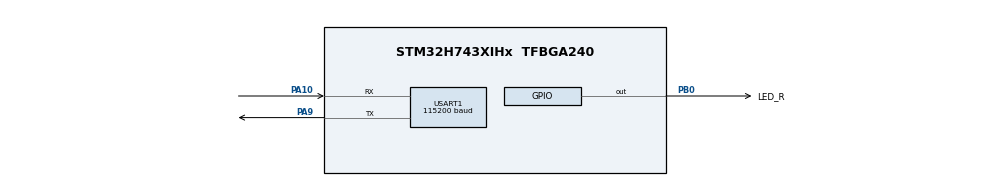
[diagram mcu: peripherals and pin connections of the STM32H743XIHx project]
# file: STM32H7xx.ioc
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CORTEX_M7.AccessPermission_S-Cortex_Memory_Protection_Unit_Region1_Settings_S=MPU_REGION_FULL_ACCESS
CORTEX_M7.AccessPermission_S-Cortex_Memory_Protection_Unit_Region2_Settings_S=MPU_REGION_FULL_ACCESS
CORTEX_M7.AccessPermission_S-Cortex_Memory_Protection_Unit_Region3_Settings_S=MPU_REGION_FULL_ACCESS
CORTEX_M7.AccessPermission_Spec=MPU_REGION_FULL_ACCESS
CORTEX_M7.BaseAddress_S-Cortex_Memory_Protection_Unit_Region1_Settings_S=0x24000000
CORTEX_M7.BaseAddress_S-Cortex_Memory_Protection_Unit_Region2_Settings_S=0x30000000
CORTEX_M7.BaseAddress_S-Cortex_Memory_Protection_Unit_Region3_Settings_S=0x38000000
CORTEX_M7.BaseAddress_Spec=0x20000000
CORTEX_M7.CPU_DCache=Enabled
CORTEX_M7.CPU_ICache=Enabled
CORTEX_M7.DisableExec_Spec=MPU_INSTRUCTION_ACCESS_ENABLE
CORTEX_M7.Enable_S-Cortex_Memory_Protection_Unit_Region1_Settings_S=MPU_REGION_ENABLE
CORTEX_M7.Enable_S-Cortex_Memory_Protection_Unit_Region2_Settings_S=MPU_REGION_ENABLE
CORTEX_M7.Enable_S-Cortex_Memory_Protection_Unit_Region3_Settings_S=MPU_REGION_ENABLE
CORTEX_M7.Enable_S-Cortex_Memory_Protection_Unit_Region4_Settings_S=__NULL
CORTEX_M7.Enable_S-Cortex_Memory_Protection_Unit_Region5_Settings_S=__NULL
CORTEX_M7.IsBufferable_S-Cortex_Memory_Protection_Unit_Region1_Settings_S=MPU_ACCESS_BUFFERABLE
CORTEX_M7.IsBufferable_S-Cortex_Memory_Protection_Unit_Region2_Settings_S=MPU_ACCESS_BUFFERABLE
CORTEX_M7.IsBufferable_S-Cortex_Memory_Protection_Unit_Region3_Settings_S=MPU_ACCESS_BUFFERABLE
CORTEX_M7.IsBufferable_Spec=MPU_ACCESS_BUFFERABLE
CORTEX_M7.IsCacheable_S-Cortex_Memory_Protection_Unit_Region1_Settings_S=MPU_ACCESS_CACHEABLE
CORTEX_M7.IsCacheable_S-Cortex_Memory_Protection_Unit_Region2_Settings_S=MPU_ACCESS_CACHEABLE
CORTEX_M7.IsCacheable_S-Cortex_Memory_Protection_Unit_Region3_Settings_S=MPU_ACCESS_CACHEABLE
CORTEX_M7.IsCacheable_Spec=MPU_ACCESS_CACHEABLE
CORTEX_M7.IsShareable_Spec=MPU_ACCESS_NOT_SHAREABLE
CORTEX_M7.Size_S-Cortex_Memory_Protection_Unit_Region1_Settings_S=MPU_REGION_SIZE_512KB
CORTEX_M7.Size_S-Cortex_Memory_Protection_Unit_Region2_Settings_S=MPU_REGION_SIZE_512KB
CORTEX_M7.Size_S-Cortex_Memory_Protection_Unit_Region3_Settings_S=MPU_REGION_SIZE_64KB
CORTEX_M7.Size_Spec=MPU_REGION_SIZE_128KB
CORTEX_M7.SubRegionDisable_Spec=0x00
CORTEX_M7.default_mode_Activation=1
Mcu.Family=STM32H7
Mcu.Name=STM32H743XIHx
Mcu.Package=TFBGA240
NVIC.PriorityGroup=NVIC_PRIORITYGROUP_2
NVIC.USART1_IRQn=true\:2\:2\:true\:false\:true\:true\:true\:true
PA10.GPIO_Speed=GPIO_SPEED_FREQ_VERY_HIGH
PA10.Mode=Asynchronous
PA10.Signal=USART1_RX
PA13\ (JTMS/SWDIO).Mode=Serial_Wire
PA13\ (JTMS/SWDIO).Signal=DEBUG_JTMS-SWDIO
PA14\ (JTCK/SWCLK).Mode=Serial_Wire
PA14\ (JTCK/SWCLK).Signal=DEBUG_JTCK-SWCLK
PA9.GPIO_Speed=GPIO_SPEED_FREQ_VERY_HIGH
PA9.Mode=Asynchronous
PA9.Signal=USART1_TX
PB0.GPIO_Label=LED_R
PB0.GPIO_PuPd=GPIO_PULLUP
PB0.GPIO_Speed=GPIO_SPEED_FREQ_HIGH
PB0.PinState=GPIO_PIN_SET
PB0.Signal=GPIO_Output
PC14-OSC32_IN\ (OSC32_IN).Mode=LSE-External-Oscillator
PC14-OSC32_IN\ (OSC32_IN).Signal=RCC_OSC32_IN
PC15-OSC32_OUT\ (OSC32_OUT).Mode=LSE-External-Oscillator
PC15-OSC32_OUT\ (OSC32_OUT).Signal=RCC_OSC32_OUT
PH0-OSC_IN\ (PH0).Mode=HSE-External-Oscillator
PH0-OSC_IN\ (PH0).Signal=RCC_OSC_IN
PH1-OSC_OUT\ (PH1).Mode=HSE-External-Oscillator
PH1-OSC_OUT\ (PH1).Signal=RCC_OSC_OUT
ProjectManager.HeapSize=0x200
ProjectManager.StackSize=0x400
ProjectManager.TargetToolchain=MDK-ARM V5.32
RCC.ADCFreq_Value=75000000
RCC.APB1Freq_Value=120000000
RCC.APB2Freq_Value=120000000
RCC.APB3Freq_Value=120000000
RCC.APB4Freq_Value=120000000
RCC.CortexFreq_Value=480000000
RCC.D1PPRE=RCC_APB3_DIV2
RCC.D2PPRE1=RCC_APB1_DIV2
RCC.D2PPRE2=RCC_APB2_DIV2
RCC.D3PPRE=RCC_APB4_DIV2
RCC.DIVM1=5
RCC.DIVM2=2
RCC.DIVN1=192
RCC.DIVN2=12
RCC.HCLKFreq_Value=240000000
RCC.HPRE=RCC_HCLK_DIV2
RCC.PLL2FRACN=0
RCC.PLL3FRACN=0
RCC.PLLFRACN=0
RCC.PLLSourceVirtual=RCC_PLLSOURCE_HSE
RCC.PWR_Regulator_Voltage_Scale=PWR_REGULATOR_VOLTAGE_SCALE0
RCC.ProductRev=revV
RCC.RCC_TIM_PRescaler_Selection=RCC_TIMPRES_ACTIVATED
RCC.SYSCLKFreq_VALUE=480000000
RCC.SYSCLKSource=RCC_SYSCLKSOURCE_PLLCLK
RCC.USBFreq_Value=480000000
RCC.VDD_VALUE=3.3
USART1.BaudRate=115200
USART1.VirtualMode-Asynchronous=VM_ASYNC
board=custom

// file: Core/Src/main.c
/* USER CODE BEGIN Header */
/**
  ******************************************************************************
  * @file           : main.c
  * @brief          : Main program body
  ******************************************************************************
  * @attention
  *
  * Copyright (c) 2023 STMicroelectronics.
  * All rights reserved.
  *
  * This software is licensed under terms that can be found in the LICENSE file
  * in the root directory of this software component.
  * If no LICENSE file comes with this software, it is provided AS-IS.
  *
  ******************************************************************************
  */
/* USER CODE END Header */
#include "main.h"
#include "usart.h"
#include "gpio.h"

/* USER CODE BEGIN Includes */

#include "stdio.h"
#include "string.h"
#include "stdlib.h"

/* USER CODE END Includes */

void SystemClock_Config(void);
void PeriphCommonClock_Config(void);
static void MPU_Config(void);

/* USER CODE BEGIN 0 */

/*
*********************************************************************************************************
*	函 数 名: PrintfLogo
*	功能说明: 打印例程名称和例程发布日期, 接上串口线后，打开PC机的超级终端软件可以观察结果
*	形    参: 无
*	返 回 值: 无
*********************************************************************************************************
*/
static void Printf_Logo(void)
{
	printf("*************************************************************\r\n");

    uint32_t CPU_Sn0, CPU_Sn1, CPU_Sn2;

    CPU_Sn0 = *(__IO uint32_t*)(0x1FF1E800);
    CPU_Sn1 = *(__IO uint32_t*)(0x1FF1E800 + 4);
    CPU_Sn2 = *(__IO uint32_t*)(0x1FF1E800 + 8);

    printf("CPU : STM32H743XIH6, BGA240, 主频: %dMHz\r\n", SystemCoreClock / 1000000);
    printf("UID = %08X %08X %08X", CPU_Sn2, CPU_Sn1, CPU_Sn0);

	printf("*************************************************************\r\n");
	printf("* 例程名称 : 串口通信\r\n");	/* 打印例程名称 */
    printf("* 例程现象 : 串口自动发送接收到的数据\r\n");	/* 打印例程名称 */

	printf("*************************************************************\r\n");
}

/* USER CODE END 0 */

int main(void)
{

  /* MPU Configuration--------------------------------------------------------*/
  MPU_Config();

  /* Enable the CPU Cache */

  /* Enable I-Cache---------------------------------------------------------*/
  SCB_EnableICache();

  /* Enable D-Cache---------------------------------------------------------*/
  SCB_EnableDCache();

  /* MCU Configuration--------------------------------------------------------*/

  /* Reset of all peripherals, Initializes the Flash interface and the Systick. */
  HAL_Init();

  /* Configure the system clock */
  SystemClock_Config();

/* Configure the peripherals common clocks */
  PeriphCommonClock_Config();

  /* Initialize all configured peripherals */
  MX_GPIO_Init();
  MX_USART1_UART_Init();
  /* USER CODE BEGIN 2 */

    Printf_Logo();

  /* USER CODE END 2 */

  /* Infinite loop */
  /* USER CODE BEGIN WHILE */
  while (1)
  {
      LED_R_TOGGLE();
      HAL_Delay(100);

    /* USER CODE END WHILE */

  }
}

void SystemClock_Config(void)
{
  RCC_OscInitTypeDef RCC_OscInitStruct = {0};
  RCC_ClkInitTypeDef RCC_ClkInitStruct = {0};

  /** Supply configuration update enable
  */
  HAL_PWREx_ConfigSupply(PWR_LDO_SUPPLY);

  /** Configure the main internal regulator output voltage
  */
  __HAL_PWR_VOLTAGESCALING_CONFIG(PWR_REGULATOR_VOLTAGE_SCALE1);

  while(!__HAL_PWR_GET_FLAG(PWR_FLAG_VOSRDY)) {}

  __HAL_RCC_SYSCFG_CLK_ENABLE();
  __HAL_PWR_VOLTAGESCALING_CONFIG(PWR_REGULATOR_VOLTAGE_SCALE0);

  while(!__HAL_PWR_GET_FLAG(PWR_FLAG_VOSRDY)) {}

  /** Initializes the RCC Oscillators according to the specified parameters
  * in the RCC_OscInitTypeDef structure.
  */
  RCC_OscInitStruct.OscillatorType = RCC_OSCILLATORTYPE_HSE;
  RCC_OscInitStruct.HSEState = RCC_HSE_ON;
  RCC_OscInitStruct.PLL.PLLState = RCC_PLL_ON;
  RCC_OscInitStruct.PLL.PLLSource = RCC_PLLSOURCE_HSE;
  RCC_OscInitStruct.PLL.PLLM = 5;
  RCC_OscInitStruct.PLL.PLLN = 192;
  RCC_OscInitStruct.PLL.PLLP = 2;
  RCC_OscInitStruct.PLL.PLLQ = 2;
  RCC_OscInitStruct.PLL.PLLR = 2;
  RCC_OscInitStruct.PLL.PLLRGE = RCC_PLL1VCIRANGE_2;
  RCC_OscInitStruct.PLL.PLLVCOSEL = RCC_PLL1VCOWIDE;
  RCC_OscInitStruct.PLL.PLLFRACN = 0;
  if (HAL_RCC_OscConfig(&RCC_OscInitStruct) != HAL_OK)
  {
    Error_Handler();
  }

  /** Initializes the CPU, AHB and APB buses clocks
  */
  RCC_ClkInitStruct.ClockType = RCC_CLOCKTYPE_HCLK|RCC_CLOCKTYPE_SYSCLK
                              |RCC_CLOCKTYPE_PCLK1|RCC_CLOCKTYPE_PCLK2
                              |RCC_CLOCKTYPE_D3PCLK1|RCC_CLOCKTYPE_D1PCLK1;
  RCC_ClkInitStruct.SYSCLKSource = RCC_SYSCLKSOURCE_PLLCLK;
  RCC_ClkInitStruct.SYSCLKDivider = RCC_SYSCLK_DIV1;
  RCC_ClkInitStruct.AHBCLKDivider = RCC_HCLK_DIV2;
  RCC_ClkInitStruct.APB3CLKDivider = RCC_APB3_DIV2;
  RCC_ClkInitStruct.APB1CLKDivider = RCC_APB1_DIV2;
  RCC_ClkInitStruct.APB2CLKDivider = RCC_APB2_DIV2;
  RCC_ClkInitStruct.APB4CLKDivider = RCC_APB4_DIV2;

  if (HAL_RCC_ClockConfig(&RCC_ClkInitStruct, FLASH_LATENCY_4) != HAL_OK)
  {
    Error_Handler();
  }
}

void PeriphCommonClock_Config(void)
{
  RCC_PeriphCLKInitTypeDef PeriphClkInitStruct = {0};

  /** Initializes the peripherals clock
  */
  PeriphClkInitStruct.PeriphClockSelection = RCC_PERIPHCLK_TIM;
  PeriphClkInitStruct.TIMPresSelection = RCC_TIMPRES_ACTIVATED;

  if (HAL_RCCEx_PeriphCLKConfig(&PeriphClkInitStruct) != HAL_OK)
  {
    Error_Handler();
  }
}

 /* MPU Configuration */

void MPU_Config(void)
{
  MPU_Region_InitTypeDef MPU_InitStruct = {0};

  /* Disables the MPU */
  HAL_MPU_Disable();

  /** Initializes and configures the Region and the memory to be protected
  */
  MPU_InitStruct.Enable = MPU_REGION_ENABLE;
  MPU_InitStruct.Number = MPU_REGION_NUMBER0;
  MPU_InitStruct.BaseAddress = 0x20000000;
  MPU_InitStruct.Size = MPU_REGION_SIZE_128KB;
  MPU_InitStruct.SubRegionDisable = 0x00;
  MPU_InitStruct.TypeExtField = MPU_TEX_LEVEL0;
  MPU_InitStruct.AccessPermission = MPU_REGION_FULL_ACCESS;
  MPU_InitStruct.DisableExec = MPU_INSTRUCTION_ACCESS_ENABLE;
  MPU_InitStruct.IsShareable = MPU_ACCESS_NOT_SHAREABLE;
  MPU_InitStruct.IsCacheable = MPU_ACCESS_CACHEABLE;
  MPU_InitStruct.IsBufferable = MPU_ACCESS_BUFFERABLE;

  HAL_MPU_ConfigRegion(&MPU_InitStruct);

  /** Initializes and configures the Region and the memory to be protected
  */
  MPU_InitStruct.Number = MPU_REGION_NUMBER1;
  MPU_InitStruct.BaseAddress = 0x24000000;
  MPU_InitStruct.Size = MPU_REGION_SIZE_512KB;
  MPU_InitStruct.SubRegionDisable = 0x0;

  HAL_MPU_ConfigRegion(&MPU_InitStruct);

  /** Initializes and configures the Region and the memory to be protected
  */
  MPU_InitStruct.Number = MPU_REGION_NUMBER2;
  MPU_InitStruct.BaseAddress = 0x30000000;

  HAL_MPU_ConfigRegion(&MPU_InitStruct);

  /** Initializes and configures the Region and the memory to be protected
  */
  MPU_InitStruct.Number = MPU_REGION_NUMBER3;
  MPU_InitStruct.BaseAddress = 0x38000000;
  MPU_InitStruct.Size = MPU_REGION_SIZE_64KB;

  HAL_MPU_ConfigRegion(&MPU_InitStruct);
  /* Enables the MPU */
  HAL_MPU_Enable(MPU_PRIVILEGED_DEFAULT);

}

void Error_Handler(void)
{
  /* USER CODE BEGIN Error_Handler_Debug */
  /* User can add his own implementation to report the HAL error return state */
  __disable_irq();
  while (1)
  {
      break;
  }
  /* USER CODE END Error_Handler_Debug */
}
